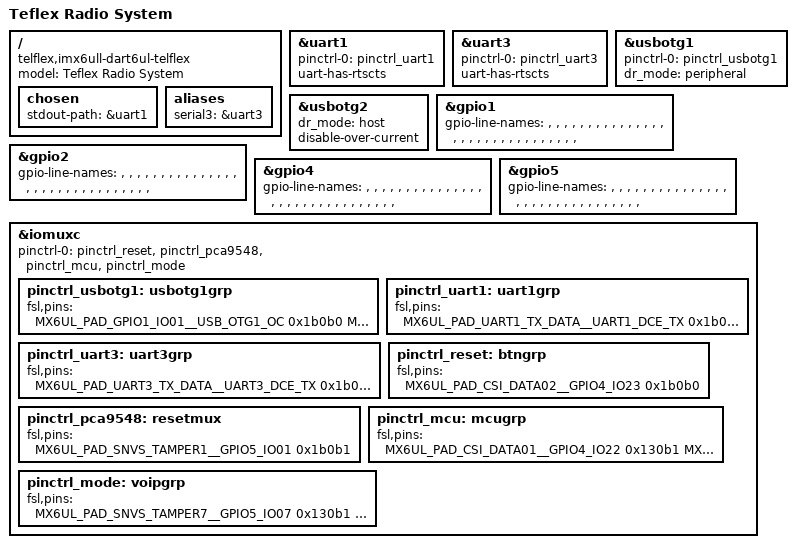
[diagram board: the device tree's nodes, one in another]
/*
 * Copyright (C) 2018 Amotus Solutions, Inc.
 */

#include "imx6ull-dart6ul.dtsi"
#include "imx6ull-dart6ul-emmc-wifi.dtsi"
#include "imx6ull-dart6ul-ethernet.dtsi"

/ {
	model = "Teflex Radio System";
	compatible = "telflex,imx6ull-dart6ul-telflex", "fsl,imx6ull";

	chosen {
		stdout-path = &uart1;
	};

    aliases {
        serial3 = &uart3; /* become /dev/ttyS3 */
    };
};

/* ttymxc0 uart - debug uart */
&uart1 {
	pinctrl-names = "default";
	pinctrl-0 = <&pinctrl_uart1>;
	uart-has-rtscts;
	status = "okay";
};

/* ttymxc2 uart - xbee */
&uart3 {
	pinctrl-names = "default";
	pinctrl-0 = <&pinctrl_uart3>;
	uart-has-rtscts;
	status = "okay";
};



&usbotg1 {
	pinctrl-names = "default";
	pinctrl-0 = <&pinctrl_usbotg1>;
	dr_mode = "peripheral";
	status = "okay";
};

&usbotg2 {
	dr_mode = "host";
	disable-over-current;
	status = "okay";
};

&gpio1 {
	gpio-line-names = "", "", "", "", "", "", "", "",
	"", "", "", "", "", "", "", "",
	"", "", "", "", "", "", "", "",
	"", "", "", "", "", "", "", "";
};

&gpio2 {
	gpio-line-names = "", "", "", "", "", "", "", "",
	"", "", "", "", "", "", "", "",
	"", "", "", "", "", "", "", "",
	"", "", "", "", "", "", "", "";
};

&gpio4 {
	gpio-line-names = "", "", "", "", "", "", "", "",
	"", "", "", "", "", "", "", "",
	"", "", "", "", "", "", "", "",
	"", "", "", "", "", "", "", "";
};

&gpio5 {
	gpio-line-names = "", "", "", "", "", "", "", "",
	"", "", "", "", "", "", "", "",
	"", "", "", "", "", "", "", "",
	"", "", "", "", "", "", "", "";
};


&iomuxc {
	pinctrl-names = "default";
	pinctrl-0 = <&pinctrl_reset &pinctrl_pca9548 &pinctrl_mcu &pinctrl_mode>;

	pinctrl_usbotg1: usbotg1grp {
		fsl,pins = <
		MX6UL_PAD_GPIO1_IO01__USB_OTG1_OC      0x1b0b0
		MX6UL_PAD_GPIO1_IO04__USB_OTG1_PWR     0x80000000
		>;
	};

    /* uart1 : Debug Uurt */
	pinctrl_uart1: uart1grp {
		fsl,pins = <
		MX6UL_PAD_UART1_TX_DATA__UART1_DCE_TX	0x1b0b1
		MX6UL_PAD_UART1_RX_DATA__UART1_DCE_RX	0x1b0b1
		MX6UL_PAD_UART1_CTS_B__UART1_DCE_CTS	0x1b0b1
		MX6UL_PAD_UART1_RTS_B__UART1_DCE_RTS	0x1b0b1
		>;
	};


    /* uart3 : VoIP Module */
	pinctrl_uart3: uart3grp {
		fsl,pins = <
		MX6UL_PAD_UART3_TX_DATA__UART3_DCE_TX	0x1b0b1 /* J1-59 */
		MX6UL_PAD_UART3_RX_DATA__UART3_DCE_RX	0x1b0b1 /* J1-61 */
		MX6UL_PAD_UART3_CTS_B__UART3_DCE_CTS	0x1b0b1 /* J1-67 */
		MX6UL_PAD_UART3_RTS_B__UART3_DCE_RTS	0x1b0b1 /* J1-69 */
		>;
	};

	pinctrl_reset: btngrp {
		fsl,pins = <
		MX6UL_PAD_CSI_DATA02__GPIO4_IO23		0x1b0b0
		>;
	};

	pinctrl_pca9548: resetmux {
		fsl,pins = <
		MX6UL_PAD_SNVS_TAMPER1__GPIO5_IO01		0x1b0b1
		>;
	};

	pinctrl_mcu: mcugrp {
		fsl,pins = <
		MX6UL_PAD_CSI_DATA01__GPIO4_IO22		0x130b1 /* J1-80 MCU BOOT0 PullDown 118 */
		MX6UL_PAD_CSI_DATA00__GPIO4_IO21		0x1b0b1 /* J1-88 MCU nRST  PullUp 117 */
		>;
	};

	pinctrl_mode: voipgrp {
		fsl,pins = <
		MX6UL_PAD_SNVS_TAMPER7__GPIO5_IO07		0x130b1 /* mode_microphone dynamic / elec PullDown 135 */
		MX6UL_PAD_JTAG_MOD__GPIO1_IO10			0x130b1 /* mode_gain_gpio PullDown 10 */
		>;
	};
};
